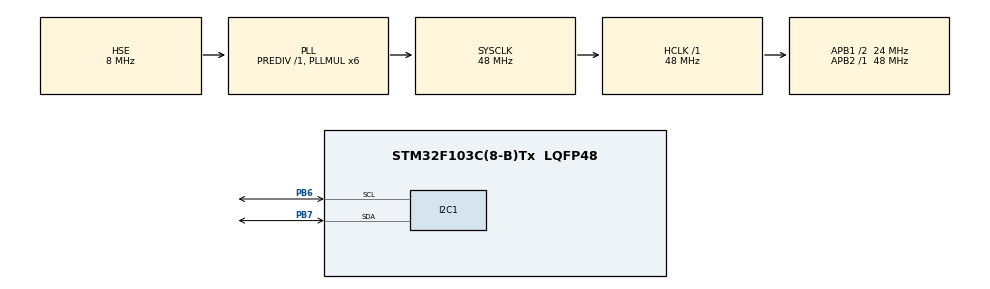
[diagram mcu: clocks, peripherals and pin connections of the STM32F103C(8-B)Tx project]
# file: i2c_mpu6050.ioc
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I2C1.I2C_Mode=I2C_Fast
Mcu.Family=STM32F1
Mcu.Name=STM32F103C(8-B)Tx
Mcu.Package=LQFP48
NVIC.PriorityGroup=NVIC_PRIORITYGROUP_4
PA13.Mode=Serial_Wire
PA13.Signal=SYS_JTMS-SWDIO
PA14.Mode=Serial_Wire
PA14.Signal=SYS_JTCK-SWCLK
PB6.Mode=I2C
PB6.Signal=I2C1_SCL
PB7.Mode=I2C
PB7.Signal=I2C1_SDA
PD0-OSC_IN.Mode=HSE-External-Oscillator
PD0-OSC_IN.Signal=RCC_OSC_IN
PD1-OSC_OUT.Mode=HSE-External-Oscillator
PD1-OSC_OUT.Signal=RCC_OSC_OUT
ProjectManager.HeapSize=0x200
ProjectManager.StackSize=0x400
ProjectManager.TargetToolchain=STM32CubeIDE
RCC.AHBFreq_Value=48000000
RCC.APB1CLKDivider=RCC_HCLK_DIV2
RCC.APB1Freq_Value=24000000
RCC.APB1TimFreq_Value=48000000
RCC.APB2Freq_Value=48000000
RCC.APB2TimFreq_Value=48000000
RCC.EnbaleCSS=true
RCC.HCLKFreq_Value=48000000
RCC.PLLMUL=RCC_PLL_MUL6
RCC.PLLSourceVirtual=RCC_PLLSOURCE_HSE
RCC.SYSCLKFreq_VALUE=48000000
RCC.SYSCLKSource=RCC_SYSCLKSOURCE_PLLCLK
RCC.USBFreq_Value=48000000
board=custom

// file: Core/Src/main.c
/* USER CODE BEGIN Header */
/**
 ******************************************************************************
 * @file           : main.c
 * @brief          : Main program body
 ******************************************************************************
 * @attention
 *
 * Copyright (c) 2024 STMicroelectronics.
 * All rights reserved.
 *
 * This software is licensed under terms that can be found in the LICENSE file
 * in the root directory of this software component.
 * If no LICENSE file comes with this software, it is provided AS-IS.
 *
 ******************************************************************************
 */
/* USER CODE END Header */
#include "main.h"

/* USER CODE BEGIN Includes */
#include "i2c_er.h"
#include "init_device.h"
#include <math.h>
/* USER CODE END Includes */

/* USER CODE BEGIN PD */
#define MPU6050_Address 0x68 << 1
#define RAD_TO_DEG 57.295779513082320876798154814105
/* USER CODE END PD */

I2C_HandleTypeDef hi2c1;

/* USER CODE BEGIN PV */
HAL_StatusTypeDef state = HAL_OK; // Результат выполнения запроса

// Переменная итератор для запроса на получение данных каждые 20 мс
volatile uint8_t uiTicksCNT = 0;

// Буффер для raw данных с датчика MPU6050
uint8_t pRxData[20];

// Буффер для считанных данных
int16_t pData[6];

// Смещения для гироскопа
int16_t gx_offset = 0;
int16_t gy_offset = 0;
int16_t gz_offset = 0;

// Флаг окончания калибровки
uint8_t isCalibrate = 0;
// Флаг готовности выполнить вычисления, 1 раз в 20 мс
volatile uint8_t isCalculation = 0;

float roll = 0;
float pitch = 0;
float yaw = 0;
/* USER CODE END PV */

void SystemClock_Config(void);
static void MX_GPIO_Init(void);
static void MX_I2C1_Init(void);
/* USER CODE BEGIN PFP */
void MPU6050_Calibrate(void);
void MPU6050_Get_All_Data(void);
/* USER CODE END PFP */

int main(void) {

  /* MCU Configuration--------------------------------------------------------*/

  /* Reset of all peripherals, Initializes the Flash interface and the Systick. */
  HAL_Init();

  /* Configure the system clock */
  SystemClock_Config();

  /* USER CODE BEGIN SysInit */
  __HAL_RCC_I2C1_CLK_ENABLE();
  HAL_Delay(100);
  __HAL_RCC_I2C1_FORCE_RESET();
  HAL_Delay(100);
  __HAL_RCC_I2C1_RELEASE_RESET();
  HAL_Delay(100);
  /* USER CODE END SysInit */

  /* Initialize all configured peripherals */
  MX_GPIO_Init();
  MX_I2C1_Init();
  /* USER CODE BEGIN 2 */
  // Проверяем готовность I2C и MLX90393
  state = HAL_I2C_IsDeviceReady(&hi2c1, (uint16_t) MPU6050_Address, 1, HAL_MAX_DELAY);
  if (state == HAL_BUSY) {
    // При данном флаге вызываем функцию переинициализации I2C1
    I2C_ClearBusyFlagErratum(&hi2c1, 1000);
  }

  // Производим инициализацию MPU6050
  state = init_MPU6050(&hi2c1, (uint16_t) MPU6050_Address);
  if (state != HAL_OK) {
    // Если при инициализации произошла ошибка, перезапускаем микроконтроллер
    __set_FAULTMASK(1); // Запрещаем все маскируемые прерывания
    NVIC_SystemReset(); // Программный сброс
  }

  // Калибруем MPU6050
  MPU6050_Calibrate();
  /* USER CODE END 2 */

  /* Infinite loop */
  /* USER CODE BEGIN WHILE */
  while (1) {
    if (isCalculation) {
      isCalculation = 0;

      // Запрос на получение данных каждые 20 мс
      MPU6050_Get_All_Data();
      // Преобразуем данные
      roll += (float) (pData[3] - gx_offset) / 65.5 / 50;
      pitch += (float) (pData[4] - gy_offset) / 65.5 / 50;
      float _yaw = (float) (pData[5] - gz_offset) / 65.5 / 50;
      yaw += _yaw;

      if (_yaw > 1 || _yaw < -1) {
        // Если произошло изменение yaw, пересчитываем pitch и roll
        float _y = sin(_yaw * 3.1415 / 180);

        pitch += roll * _y;
        roll -= pitch * _y;
      }

      // Работа с акселерометром
      float roll4macc = atan2(pData[1], (sqrt(pow(pData[0], 2) + pow(pData[2], 2)))) * RAD_TO_DEG;
      float pitch4macc = atan2(pData[0], (sqrt(pow(pData[1], 2) + pow(pData[2], 2)))) * RAD_TO_DEG;

      float koef = 0.1;
      pitch = pitch * (1 - koef) + pitch4macc * koef;
      roll = roll * (1 - koef) + roll4macc * koef;
    }
    /* USER CODE END WHILE */
  }
}

void SystemClock_Config(void) {
  RCC_OscInitTypeDef RCC_OscInitStruct = { 0 };
  RCC_ClkInitTypeDef RCC_ClkInitStruct = { 0 };

  /** Initializes the RCC Oscillators according to the specified parameters
   * in the RCC_OscInitTypeDef structure.
   */
  RCC_OscInitStruct.OscillatorType = RCC_OSCILLATORTYPE_HSE;
  RCC_OscInitStruct.HSEState = RCC_HSE_ON;
  RCC_OscInitStruct.HSEPredivValue = RCC_HSE_PREDIV_DIV1;
  RCC_OscInitStruct.HSIState = RCC_HSI_ON;
  RCC_OscInitStruct.PLL.PLLState = RCC_PLL_ON;
  RCC_OscInitStruct.PLL.PLLSource = RCC_PLLSOURCE_HSE;
  RCC_OscInitStruct.PLL.PLLMUL = RCC_PLL_MUL6;
  if (HAL_RCC_OscConfig(&RCC_OscInitStruct) != HAL_OK) {
    Error_Handler();
  }

  /** Initializes the CPU, AHB and APB buses clocks
   */
  RCC_ClkInitStruct.ClockType = RCC_CLOCKTYPE_HCLK | RCC_CLOCKTYPE_SYSCLK | RCC_CLOCKTYPE_PCLK1 | RCC_CLOCKTYPE_PCLK2;
  RCC_ClkInitStruct.SYSCLKSource = RCC_SYSCLKSOURCE_PLLCLK;
  RCC_ClkInitStruct.AHBCLKDivider = RCC_SYSCLK_DIV1;
  RCC_ClkInitStruct.APB1CLKDivider = RCC_HCLK_DIV2;
  RCC_ClkInitStruct.APB2CLKDivider = RCC_HCLK_DIV1;

  if (HAL_RCC_ClockConfig(&RCC_ClkInitStruct, FLASH_LATENCY_1) != HAL_OK) {
    Error_Handler();
  }

  /** Enables the Clock Security System
   */
  HAL_RCC_EnableCSS();
}

static void MX_I2C1_Init(void) {

  hi2c1.Instance = I2C1;
  hi2c1.Init.ClockSpeed = 400000;
  hi2c1.Init.DutyCycle = I2C_DUTYCYCLE_2;
  hi2c1.Init.OwnAddress1 = 0;
  hi2c1.Init.AddressingMode = I2C_ADDRESSINGMODE_7BIT;
  hi2c1.Init.DualAddressMode = I2C_DUALADDRESS_DISABLE;
  hi2c1.Init.OwnAddress2 = 0;
  hi2c1.Init.GeneralCallMode = I2C_GENERALCALL_DISABLE;
  hi2c1.Init.NoStretchMode = I2C_NOSTRETCH_DISABLE;
  if (HAL_I2C_Init(&hi2c1) != HAL_OK) {
    Error_Handler();
  }

}

static void MX_GPIO_Init(void) {

  /* GPIO Ports Clock Enable */
  __HAL_RCC_GPIOD_CLK_ENABLE();
  __HAL_RCC_GPIOA_CLK_ENABLE();
  __HAL_RCC_GPIOB_CLK_ENABLE();

}

/* USER CODE BEGIN 4 */
void HAL_SYSTICK_Callback(void) {
  if (isCalibrate && uiTicksCNT >= 20) {
    uiTicksCNT = 0;

    isCalculation = 1;
    return;
  }
  uiTicksCNT++;
}

void MPU6050_Calibrate(void) {
  int32_t gx_cal = 0;
  int32_t gy_cal = 0;
  int32_t gz_cal = 0;
  // Калибровку выполняем за 3 секунды, 1000 итераций * 3 мс
  uint16_t count = 1000;
  for (uint16_t i = 0; i < count; i++) {
    MPU6050_Get_All_Data();
    gx_cal += pData[3];
    gy_cal += pData[4];
    gz_cal += pData[5];
    HAL_Delay(3);
  }
  gx_offset = (int16_t) (gx_cal / count);
  gy_offset = (int16_t) (gy_cal / count);
  gz_offset = (int16_t) (gz_cal / count);

  // Выставляем флаг о завершении калибровки
  isCalibrate = 1;
}

void MPU6050_Get_All_Data(void) {
  uint16_t ACCEL_XOUT_H = 0x3B;
  // Выполняем запрос на считывание всех данных
  state = HAL_I2C_Mem_Read(&hi2c1, (uint16_t) MPU6050_Address, ACCEL_XOUT_H, 1, pRxData, 14, HAL_MAX_DELAY);
  if (state == HAL_OK) {
    // Формируем 16 битные данные для осей акселерометра
    pData[0] = (int16_t) pRxData[0] << 8 | pRxData[1];    // X
    pData[1] = (int16_t) pRxData[2] << 8 | pRxData[3];    // Y
    pData[2] = (int16_t) pRxData[4] << 8 | pRxData[5];    // Z
    // Формируем 16 битные данные для осей гироскопа
    pData[3] = (int16_t) pRxData[8] << 8 | pRxData[9];    // X
    pData[4] = (int16_t) pRxData[10] << 8 | pRxData[11];  // Y
    pData[5] = (int16_t) pRxData[12] << 8 | pRxData[13];  // Z
  }
}
/* USER CODE END 4 */

void Error_Handler(void) {
  __disable_irq();
  while (1) {
  }
}
